# GD32C10x register map
File version: 1.0
CPU: CM4 r2p1, little endian, no MPU, FPU, 4 interrupt priority bits
Registers are 32-bit, read-write, reset 0x0 unless marked. A register's access mark holds for its fields unless they carry their own. Offsets are from the block's base; [hi:lo] are bit positions; {n}, {i} and the like mark numbered series.

## FWDGT — free watchdog timer
Base 0x40003000
0x00 CTL wo — Control register
  [15:0] CMD — Key value
0x04 PSC — Prescaler register
  [2:0] PSC — Free watchdog timer prescaler selection
0x08 RLD reset 0xFFF — Reload register
  [11:0] RLD — Free watchdog timer counter reload value
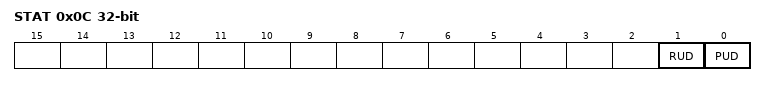
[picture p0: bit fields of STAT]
0x0C STAT ro — Status register
  [1] RUD — Free watchdog timer counter reload value update
  [0] PUD — Free watchdog timer prescaler value update

## GPIOA — General-purpose I/Os
Base 0x40010800
Same registers: GPIOB 0x40010C00, GPIOC 0x40011000, GPIOD 0x40011400, GPIOE 0x40011800
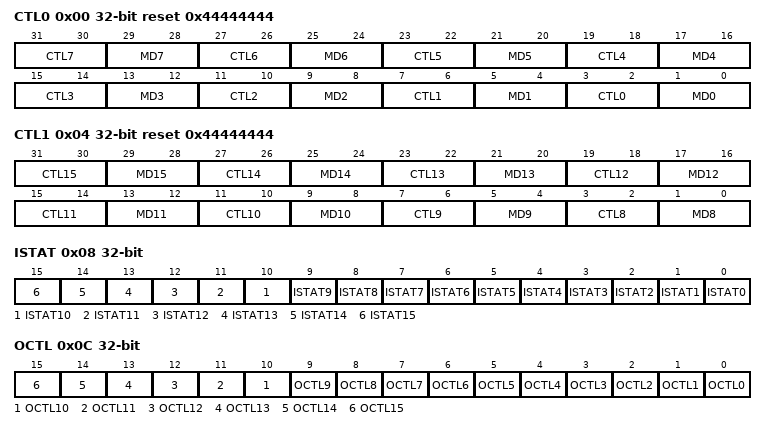
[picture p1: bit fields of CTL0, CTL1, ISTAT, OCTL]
0x00 CTL0 reset 0x44444444 — port control register 0
  [4n+3:4n+2] CTL{n} (n=0..7) — Port x configuration bits (x = {n})
  [4n+1:4n] MD{n} (n=4..7) — Port x mode bits (x = {n})
  [13:12] MD3 — Port x mode bits (x = 3 )
  [9:8] MD2 — Port x mode bits (x = 2 )
  [5:4] MD1 — Port x mode bits (x = 1)
  [1:0] MD0 — Port x mode bits (x = 0)
0x04 CTL1 reset 0x44444444 — port control register 1
  [4n-29:4n-30] CTL{n} (n=8..15) — Port x configuration bits (x = {n})
  [4n-31:4n-32] MD{n} (n=12..15) — Port x mode bits (x = {n})
  [13:12] MD11 — Port x mode bits (x = 11 )
  [9:8] MD10 — Port x mode bits (x = 10 )
  [5:4] MD9 — Port x mode bits (x = 9)
  [1:0] MD8 — Port x mode bits (x = 8)
0x08 ISTAT ro — Port input status register
  [n] ISTAT{n} (n=0..15) — Port input status
0x0C OCTL — Port output control register
  [n] OCTL{n} (n=0..15) — Port output control
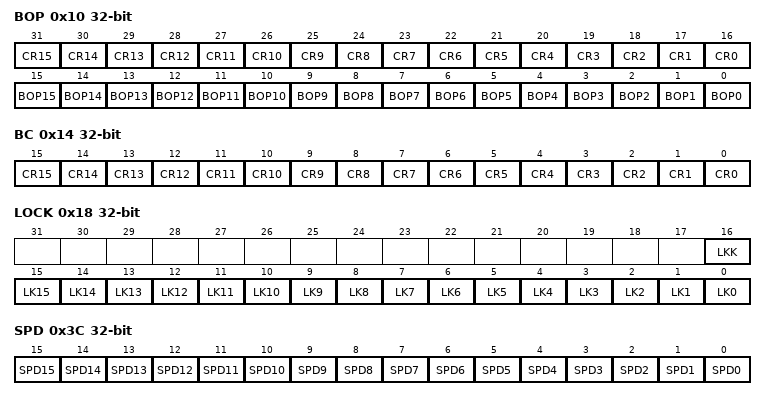
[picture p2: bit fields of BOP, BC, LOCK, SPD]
0x10 BOP wo — Port bit operate register
  [n+16] CR{n} (n=0..15) — Port {n} Clear bit
  [n] BOP{n} (n=0..15) — Port {n} Set bit
0x14 BC wo — Port bit clear register
  [n] CR{n} (n=0..15) — Port {n} Clear bit
0x18 LOCK — GPIO port configuration lock register
  [16] LKK — Lock sequence key
  [n] LK{n} (n=0..15) — Port Lock bit {n}
0x3C SPD — Port bit speed register
  [n] SPD{n} (n=0..15) — Port {n} output max speed bits

## NVIC — Nested Vectored Interrupt Controller
Base 0xE000E100
0x00 ISER — Interrupt Set Enable Register
  [31:0] SETENA
0x80 ICER — Interrupt Clear Enable Register
  [31:0] CLRENA
0x100 ISPR — Interrupt Set-Pending Register
  [31:0] SETPEND
0x180 ICPR — Interrupt Clear-Pending Register
  [31:0] CLRPEND
0x200 IABR — Interrupt Active bit Register
{0x300+i} IPR{i} 8-bit (i=0..67) — Interrupt Priority Register {i}
  [7:0] PRI_{i:02}
0xE00 STIR wo — Software Trigger Interrupt Register

## PMU — Power management unit
Base 0x40007000
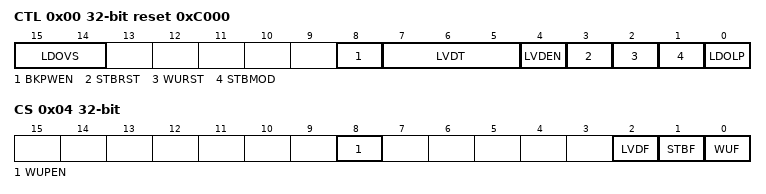
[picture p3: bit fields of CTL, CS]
0x00 CTL reset 0xC000 — power control register
  [15:14] LDOVS — LDO output voltage select
  [8] BKPWEN — Backup Domain Write Enable
  [7:5] LVDT — Low Voltage Detector Threshold
  [4] LVDEN — Low Voltage Detector Enable
  [3] STBRST — Standby Flag Reset
  [2] WURST — Wakeup Flag Reset
  [1] STBMOD — Standby Mode
  [0] LDOLP — LDO Low Power Mode
0x04 CS access per field — power control/status register
  [8] WUPEN rw — Enable WKUP pin
  [2] LVDF ro — Low Voltage Detector Status Flag
  [1] STBF ro — Standby flag
  [0] WUF ro — Wakeup flag

## RTC — Real-time clock
Base 0x40002800
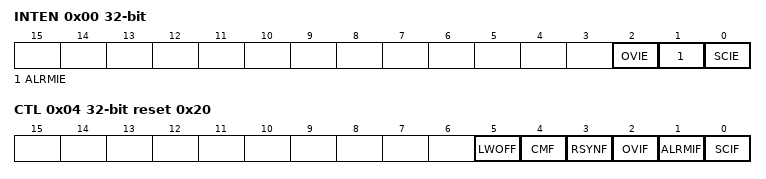
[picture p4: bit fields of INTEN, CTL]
0x00 INTEN — RTC interrupt enable register
  [2] OVIE — Overflow interrupt enable
  [1] ALRMIE — Alarm interrupt enable
  [0] SCIE — Second interrupt
0x04 CTL reset 0x20 — control register
  [5] LWOFF — Last write operation finished flag
  [4] CMF — Configuration mode flag
  [3] RSYNF — Registers synchronized flag
  [2] OVIF — Overflow interrupt flag
  [1] ALRMIF — Alarm interrupt flag
  [0] SCIF — Sencond interrupt flag
0x08 PSCH wo — RTC prescaler high register
  [3:0] PSC — RTC prescaler value high
0x0C PSCL wo reset 0x8000 — RTC prescaler low register
  [15:0] PSC — RTC prescaler value low
0x10 DIVH ro — RTC divider high register
  [3:0] DIV — RTC divider value high
0x14 DIVL ro reset 0x8000 — RTC divider low register
  [15:0] DIV — RTC divider value low
0x18 CNTH — RTC counter high register
  [15:0] CNT — RTC counter value high
0x1C CNTL — RTC counter low register
  [15:0] CNT — RTC conuter value low
0x20 ALRMH write reset 0xFFFF — Alarm high register
  [15:0] ALRM — Alarm value high
0x24 ALRML write reset 0xFFFF — RTC alarm low register
  [15:0] ALRM — alarm value low
